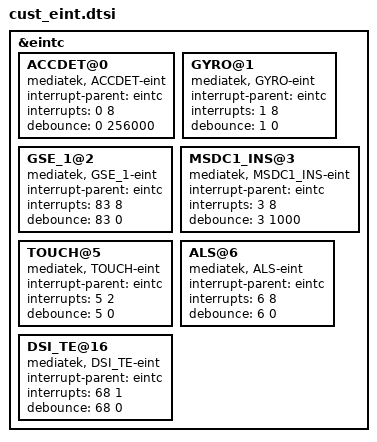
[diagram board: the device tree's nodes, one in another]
/*
 * Generated by MTK SP DrvGen Version 03.13.6 for MT6580. Copyright MediaTek Inc. (C) 2013.
 * Thu Dec 13 18:34:51 2018
 * Do Not Modify the File.
 */

/*************************
 * EINT DTSI File
*************************/

&eintc {
	ACCDET@0 {
		compatible = "mediatek, ACCDET-eint";
		interrupt-parent = <&eintc>;
		interrupts = <0 8>;
		debounce = <0 256000>;
	};

	GYRO@1 {
		compatible = "mediatek, GYRO-eint";
		interrupt-parent = <&eintc>;
		interrupts = <1 8>;
		debounce = <1 0>;
	};

	GSE_1@2 {
		compatible = "mediatek, GSE_1-eint";
		interrupt-parent = <&eintc>;
		interrupts = <83 8>;
		debounce = <83 0>;
	};

	MSDC1_INS@3 {
		compatible = "mediatek, MSDC1_INS-eint";
		interrupt-parent = <&eintc>;
		interrupts = <3 8>;
		debounce = <3 1000>;
	};

	TOUCH@5 {
		compatible = "mediatek, TOUCH-eint";
		interrupt-parent = <&eintc>;
		interrupts = <5 2>;
		debounce = <5 0>;
	};

	ALS@6 {
		compatible = "mediatek, ALS-eint";
		interrupt-parent = <&eintc>;
		interrupts = <6 8>;
		debounce = <6 0>;
	};

	DSI_TE@16 {
		compatible = "mediatek, DSI_TE-eint";
		interrupt-parent = <&eintc>;
		interrupts = <68 1>;
		debounce = <68 0>;
	};

};
